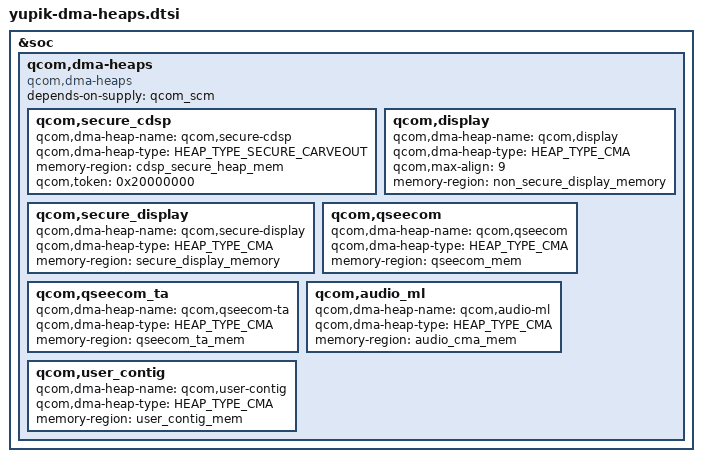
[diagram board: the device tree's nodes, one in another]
// SPDX-License-Identifier: BSD-3-Clause
/*
 * Copyright (c) 2025 Qualcomm Innovation Center, Inc. All rights reserved.
 */

#include <dt-bindings/arm/msm/qcom_dma_heap_dt_constants.h>

&soc {
	qcom,dma-heaps {
		compatible = "qcom,dma-heaps";
		depends-on-supply = <&qcom_scm>;

		 qcom,secure_cdsp {
			qcom,dma-heap-name = "qcom,secure-cdsp";
			qcom,dma-heap-type = <HEAP_TYPE_SECURE_CARVEOUT>;
			memory-region = <&cdsp_secure_heap_mem>;
			qcom,token = <0x20000000>;
		};

		qcom,display {
			qcom,dma-heap-name = "qcom,display";
			qcom,dma-heap-type = <HEAP_TYPE_CMA>;
			qcom,max-align = <9>;
			memory-region = <&non_secure_display_memory>;
		};

		qcom,secure_display {
			qcom,dma-heap-name = "qcom,secure-display";
			qcom,dma-heap-type = <HEAP_TYPE_CMA>;
			memory-region = <&secure_display_memory>;
		};

		qcom,qseecom {
			qcom,dma-heap-name = "qcom,qseecom";
			qcom,dma-heap-type = <HEAP_TYPE_CMA>;
			memory-region = <&qseecom_mem>;
		};

		qcom,qseecom_ta {
			qcom,dma-heap-name = "qcom,qseecom-ta";
			qcom,dma-heap-type = <HEAP_TYPE_CMA>;
			memory-region = <&qseecom_ta_mem>;
		};

		 qcom,audio_ml {
			qcom,dma-heap-name = "qcom,audio-ml";
			qcom,dma-heap-type = <HEAP_TYPE_CMA>;
			memory-region = <&audio_cma_mem>;
		};

		qcom,user_contig {
			qcom,dma-heap-name = "qcom,user-contig";
			qcom,dma-heap-type = <HEAP_TYPE_CMA>;
			memory-region = <&user_contig_mem>;
		};
	};
};
